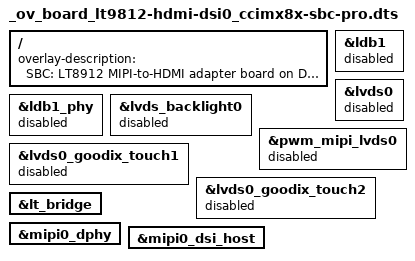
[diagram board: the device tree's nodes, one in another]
/*
 * Copyright 2020 Digi International Inc.
 *
 * Permission to use, copy, modify, and/or distribute this software for any
 * purpose with or without fee is hereby granted, provided that the above
 * copyright notice and this permission notice appear in all copies.
 * THE SOFTWARE IS PROVIDED "AS IS" AND THE AUTHOR DISCLAIMS ALL WARRANTIES
 * WITH REGARD TO THIS SOFTWARE INCLUDING ALL IMPLIED WARRANTIES OF
 * MERCHANTABILITY AND FITNESS. IN NO EVENT SHALL THE AUTHOR BE LIABLE FOR
 * ANY SPECIAL, DIRECT, INDIRECT, OR CONSEQUENTIAL DAMAGES OR ANY DAMAGES
 * WHATSOEVER RESULTING FROM LOSS OF USE, DATA OR PROFITS, WHETHER IN AN
 * ACTION OF CONTRACT, NEGLIGENCE OR OTHER TORTIOUS ACTION, ARISING OUT OF
 * OR IN CONNECTION WITH THE USE OR PERFORMANCE OF THIS SOFTWARE.
 */

/dts-v1/;
/plugin/;

/ {
	fragment@0 {
		target-path = "/";
		__overlay__ {
			overlay-description = "SBC: LT8912 MIPI-to-HDMI adapter board on DSI0";
		};
	};

	fragment@1 {
		target = <&ldb1>;
		__overlay__ {
			status = "disabled";
		};
	};

	fragment@2 {
		target = <&ldb1_phy>;
		__overlay__ {
			status = "disabled";
		};
	};

	fragment@3 {
		target = <&lvds0>;
		__overlay__ {
			status = "disabled";
		};
	};

	fragment@4 {
		target = <&lvds_backlight0>;
		__overlay__ {
			status = "disabled";
		};
	};

	fragment@5 {
		target = <&pwm_mipi_lvds0>;
		__overlay__ {
			status = "disabled";
		};
	};

	fragment@6 {
		target = <&lvds0_goodix_touch1>;
		__overlay__ {
			status = "disabled";
		};
	};

	fragment@7 {
		target = <&lvds0_goodix_touch2>;
		__overlay__ {
			status = "disabled";
		};
	};

	fragment@8 {
		target = <&lt_bridge>;
		__overlay__ {
			status = "okay";
		};
	};

	fragment@9 {
		target = <&mipi0_dphy>;
		__overlay__ {
			status = "okay";
		};
	};

	fragment@10 {
		target = <&mipi0_dsi_host>;
		__overlay__ {
			status = "okay";
		};
	};
};
